# DA1469x register map
Vendor: Dialog; Series: DA1469x; File version: 1.2
CPU: CM33 r1p0, little endian, no MPU, FPU, 3 interrupt priority bits
Registers are 32-bit, read-write, reset 0x0 unless marked. A register's access mark holds for its fields unless they carry their own. Offsets are from the block's base; [hi:lo] are bit positions; {n}, {i} and the like mark numbered series.

## MEMCTRL — MEMCTRL registers
Base 0x50050000
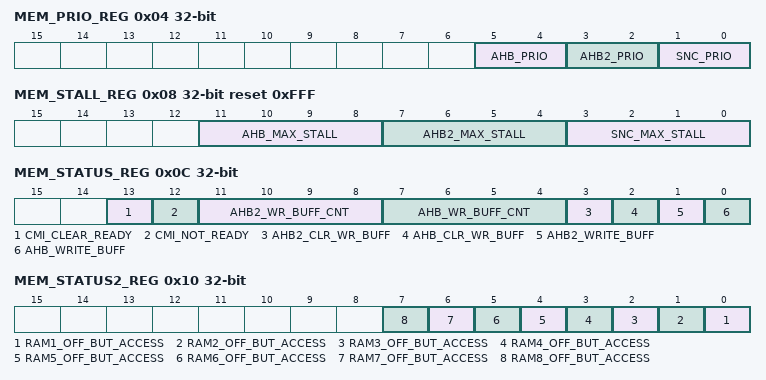
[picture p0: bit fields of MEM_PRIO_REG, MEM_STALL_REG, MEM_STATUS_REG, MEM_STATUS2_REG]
0x04 MEM_PRIO_REG — Priority Control Register
  [5:4] AHB_PRIO — Priority for the AHB interface. 00: low priority (default) 01: mid priority 1x: high priority
  [3:2] AHB2_PRIO — Priority for the AHB2 interface. 00: low priority (default) 01: mid priority 1x: high priority
  [1:0] SNC_PRIO — Priority for the SNC interface. 00: low priority (default) 01: mid priority 1x: high priority
0x08 MEM_STALL_REG reset 0xFFF — Maximum Stall cycles Control Register
  [11:8] AHB_MAX_STALL — Maximum allowed number of stall cycles for the AHB interface. If exceeded, the interface will get top priority (above high priority). Valid for a single access so the next access (of a burst) might end up in the que for the same number of wait cycles. 0: don't use, not feasible and can block other interfaces 1: max 1 stall cycle 15: max 15 stall cycles
  [7:4] AHB2_MAX_STALL — Maximum allowed number of stall cycles for the AHB2 interface. If exceeded, the interface will get top priority (above high priority). Valid for a single access so the next access (of a burst) might end up in the que for the same number of wait cycles. 0: don't use, not feasible and can block other interfaces 1: max 1 stall cycle 15: max 15 stall cycles
  [3:0] SNC_MAX_STALL — Maximum allowed number of stall cycles for the SNC interface. If exceeded, the interface will get top priority (above high priority). Valid for a single access so the next access (of a burst) might end up in the que for the same number of wait cycles. 0: don't use, not feasible and can block other interfaces 1: max 1 stall cycle 15: max 15 stall cycles
0x0C MEM_STATUS_REG — Memory Arbiter Status Register
  [13] CMI_CLEAR_READY wo — Writing a '1' clears CMI_NOT_READY bit.
  [12] CMI_NOT_READY ro — 0: Normal operation 1: CMI access performed which couldn't be handled right away (interface doesn't allow wait cycles)
  [11:8] AHB2_WR_BUFF_CNT ro — The maximum number of arbiter clock cycles that an AHB2 access has been buffered.
  [7:4] AHB_WR_BUFF_CNT ro — The maximum number of arbiter clock cycles that an AHB access has been buffered.
  [3] AHB2_CLR_WR_BUFF wo — Writing a '1' clears AHB2_WR_BUFF_CNT.
  [2] AHB_CLR_WR_BUFF wo — Writing a '1' clears AHB_WR_BUFF_CNT.
  [1] AHB2_WRITE_BUFF ro — 0: No AHB2 write access is buffered. 1: Currently a single AHB2 write access is buffered in the arbiter.
  [0] AHB_WRITE_BUFF ro — 0: No AHB write access is buffered. 1: Currently a single AHB write access is buffered in the arbiter.
0x10 MEM_STATUS2_REG — RAM cells Status Register
  [n-1] RAM{n}_OFF_BUT_ACCESS (n=1..8) — Reading a '1' indicates RAM{n} was off but still access was performed. Writing a '1' will clear the status back to '0'.
0x20 CMI_CODE_BASE_REG — CMAC code Base Address Register
  [18:10] CMI_CODE_BASE_ADDR — Base address for CMAC code with steps of 1 kB. 0x001: 1 kB base address 0x010: 16 kB base address 0x100: 256 kB base address
0x24 CMI_DATA_BASE_REG — CMAC data Base Address Register
  [18:2] CMI_DATA_BASE_ADDR — Base address for CMAC data with steps of 4 bytes. 0x00001: 4 byte base address 0x00010: 64 byte base address 0x00100: 1 kB base address 0x01000: 16 kB base address 0x10000: 256 kB base address
0x28 CMI_SHARED_BASE_REG — CMAC shared data Base Address Register
  [18:10] CMI_SHARED_BASE_ADDR — Base address for CMAC shared data with steps of 1 kB. 0x001: 1 kB base address 0x010: 16 kB base address 0x100: 256 kB base address
0x2C CMI_END_REG reset 0x7FFFF — CMAC end Address Register
  [18:10] CMI_END_ADDR — End address for CMAC code and data accesses with steps of 1 kB. 0x000: accesses up to 1kB are allowed 0x001: accesses up to 2kB are allowed 0x01F: accesses up to 32kB are allowed 0x1FF: accesses up to 512kB are allowed
0x30 SNC_BASE_REG — Sensor Node Controller Base Address Register
  [18:2] SNC_BASE_ADDRESS — Base address for SNC interface with steps of 4 bytes. 0x00001: 4 byte base address 0x00010: 64 byte base address 0x00100: 1 kB base address 0x01000: 16 kB base address 0x10000: 256 kB base address
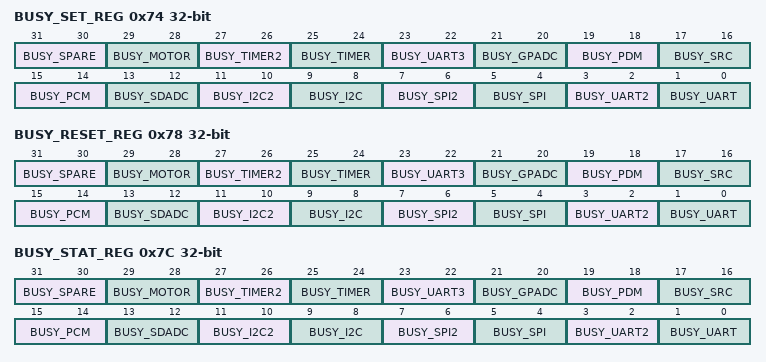
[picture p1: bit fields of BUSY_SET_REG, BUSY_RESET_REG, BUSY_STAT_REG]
0x74 BUSY_SET_REG (reset mask 0x7FFFFFFF) — BSR Set Register
  [31:30] BUSY_SPARE write-once — Writing a non-zero value to this field sets the corresponding BUSY bit, but only if it was not claimed (BUSY=0). Reading returns 0 to allow read/modify/write to the register.
  [29:28] BUSY_MOTOR write-once — Writing a non-zero value to this field sets the corresponding BUSY bit, but only if it was not claimed (BUSY=0). Reading returns 0 to allow read/modify/write to the register.
  [27:26] BUSY_TIMER2 write-once — Writing a non-zero value to this field sets the corresponding BUSY bit, but only if it was not claimed (BUSY=0). Reading returns 0 to allow read/modify/write to the register.
  [25:24] BUSY_TIMER write-once — Writing a non-zero value to this field sets the corresponding BUSY bit, but only if it was not claimed (BUSY=0). Reading returns 0 to allow read/modify/write to the register.
  [23:22] BUSY_UART3 write-once — Writing a non-zero value to this field sets the corresponding BUSY bit, but only if it was not claimed (BUSY=0). Reading returns 0 to allow read/modify/write to the register.
  [21:20] BUSY_GPADC write-once — Writing a non-zero value to this field sets the corresponding BUSY bit, but only if it was not claimed (BUSY=0). Reading returns 0 to allow read/modify/write to the register.
  [19:18] BUSY_PDM write-once — Writing a non-zero value to this field sets the corresponding BUSY bit, but only if it was not claimed (BUSY=0). Reading returns 0 to allow read/modify/write to the register.
  [17:16] BUSY_SRC write-once — Writing a non-zero value to this field sets the corresponding BUSY bit, but only if it was not claimed (BUSY=0). Reading returns 0 to allow read/modify/write to the register.
  [15:14] BUSY_PCM write-once — Writing a non-zero value to this field sets the corresponding BUSY bit, but only if it was not claimed (BUSY=0). Reading returns 0 to allow read/modify/write to the register.
  [13:12] BUSY_SDADC write-once — Writing a non-zero value to this field sets the corresponding BUSY bit, but only if it was not claimed (BUSY=0). Reading returns 0 to allow read/modify/write to the register.
  [11:10] BUSY_I2C2 write-once — Writing a non-zero value to this field sets the corresponding BUSY bit, but only if it was not claimed (BUSY=0). Reading returns 0 to allow read/modify/write to the register.
  [9:8] BUSY_I2C write-once — Writing a non-zero value to this field sets the corresponding BUSY bit, but only if it was not claimed (BUSY=0). Reading returns 0 to allow read/modify/write to the register.
  [7:6] BUSY_SPI2 write-once — Writing a non-zero value to this field sets the corresponding BUSY bit, but only if it was not claimed (BUSY=0). Reading returns 0 to allow read/modify/write to the register.
  [5:4] BUSY_SPI write-once — Writing a non-zero value to this field sets the corresponding BUSY bit, but only if it was not claimed (BUSY=0). Reading returns 0 to allow read/modify/write to the register.
  [3:2] BUSY_UART2 write-once — Writing a non-zero value to this field sets the corresponding BUSY bit, but only if it was not claimed (BUSY=0). Reading returns 0 to allow read/modify/write to the register.
  [1:0] BUSY_UART write-once — Writing a non-zero value to this field sets the corresponding BUSY bit, but only if it was not claimed (BUSY=0). Reading returns 0 to allow read/modify/write to the register.
0x78 BUSY_RESET_REG (reset mask 0x7FFFFFFF) — BSR Reset Register
  [31:30] BUSY_SPARE — Clear the BUSY bitfield, by writing the master code which has claimed to this field Reading returns 0 to allow read/modify/write to the register.
  [29:28] BUSY_MOTOR — Clear the BUSY bitfield, by writing the master code which has claimed to this field Reading returns 0 to allow read/modify/write to the register.
  [27:26] BUSY_TIMER2 — Clear the BUSY bitfield, by writing the master code which has claimed to this field Reading returns 0 to allow read/modify/write to the register.
  [25:24] BUSY_TIMER — Clear the BUSY bitfield, by writing the master code which has claimed to this field Reading returns 0 to allow read/modify/write to the register.
  [23:22] BUSY_UART3 — Clear the BUSY bitfield, by writing the master code which has claimed to this field Reading returns 0 to allow read/modify/write to the register.
  [21:20] BUSY_GPADC — Clear the BUSY bitfield, by writing the master code which has claimed to this field Reading returns 0 to allow read/modify/write to the register.
  [19:18] BUSY_PDM — Clear the BUSY bitfield, by writing the master code which has claimed to this field Reading returns 0 to allow read/modify/write to the register.
  [17:16] BUSY_SRC — Clear the BUSY bitfield, by writing the master code which has claimed to this field Reading returns 0 to allow read/modify/write to the register.
  [15:14] BUSY_PCM — Clear the BUSY bitfield, by writing the master code which has claimed to this field Reading returns 0 to allow read/modify/write to the register.
  [13:12] BUSY_SDADC — Clear the BUSY bitfield, by writing the master code which has claimed to this field Reading returns 0 to allow read/modify/write to the register.
  [11:10] BUSY_I2C2 — Clear the BUSY bitfield, by writing the master code which has claimed to this field Reading returns 0 to allow read/modify/write to the register.
  [9:8] BUSY_I2C — Clear the BUSY bitfield, by writing the master code which has claimed to this field Reading returns 0 to allow read/modify/write to the register.
  [7:6] BUSY_SPI2 — Clear the BUSY bitfield, by writing the master code which has claimed to this field Reading returns 0 to allow read/modify/write to the register.
  [5:4] BUSY_SPI — Clear the BUSY bitfield, by writing the master code which has claimed to this field Reading returns 0 to allow read/modify/write to the register.
  [3:2] BUSY_UART2 — Clear the BUSY bitfield, by writing the master code which has claimed to this field Reading returns 0 to allow read/modify/write to the register.
  [1:0] BUSY_UART — Clear the BUSY bitfield, by writing the master code which has claimed to this field Reading returns 0 to allow read/modify/write to the register.
0x7C BUSY_STAT_REG (reset mask 0x7FFFFFFF) — BSR Status Register
  [31:30] BUSY_SPARE ro — A non-zero value indicates the resource is busy. The value represents which master is using it.
  [29:28] BUSY_MOTOR ro — A non-zero value indicates the resource is busy. The value represents which master is using it.
  [27:26] BUSY_TIMER2 ro — A non-zero value indicates the resource is busy. The value represents which master is using it.
  [25:24] BUSY_TIMER ro — A non-zero value indicates the resource is busy. The value represents which master is using it.
  [23:22] BUSY_UART3 ro — A non-zero value indicates the resource is busy. The value represents which master is using it.
  [21:20] BUSY_GPADC ro — A non-zero value indicates the resource is busy. The value represents which master is using it.
  [19:18] BUSY_PDM ro — A non-zero value indicates the resource is busy. The value represents which master is using it.
  [17:16] BUSY_SRC ro — A non-zero value indicates the resource is busy. The value represents which master is using it.
  [15:14] BUSY_PCM ro — A non-zero value indicates the resource is busy. The value represents which master is using it.
  [13:12] BUSY_SDADC ro — A non-zero value indicates the resource is busy. The value represents which master is using it.
  [11:10] BUSY_I2C2 ro — A non-zero value indicates the resource is busy. The value represents which master is using it.
  [9:8] BUSY_I2C ro — A non-zero value indicates the resource is busy. The value represents which master is using it.
  [7:6] BUSY_SPI2 ro — A non-zero value indicates the resource is busy. The value represents which master is using it.
  [5:4] BUSY_SPI ro — A non-zero value indicates the resource is busy. The value represents which master is using it.
  [3:2] BUSY_UART2 ro — A non-zero value indicates the resource is busy. The value represents which master is using it.
  [1:0] BUSY_UART ro — A non-zero value indicates the resource is busy. The value represents which master is using it.
